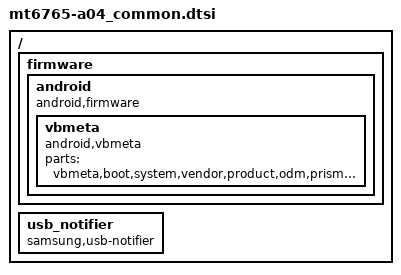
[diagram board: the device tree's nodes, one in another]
/* Generated by Samsung for MTK vendor board 

 * If these files should be changed, then please make a sync with MTK
*/

#include "samsung/modem-MTKcommon-pdata.dtsi"

/* Add Samsung configuration over here */
/ {
	fragment@model {
		target-path = "/";
		__overlay__ {
                        firmware {
                                android {
                                        compatible = "android,firmware";
                                        vbmeta {
                                                compatible = "android,vbmeta";
                                                parts = "vbmeta,boot,system,vendor,product,odm,prism,optics,vbmeta_system,recovery,lk,tee1";
                                        };
                                };
                        };

			usb_notifier {
				compatible = "samsung,usb-notifier";
			};
		};
	};
};
